# LPC800 register map
File version: 0.2
CPU: CM0 r0p0, little endian, no MPU, no FPU, 2 interrupt priority bits
Registers are 32-bit, read-write, reset 0x0 unless marked. A register's access mark holds for its fields unless they carry their own. Offsets are from the block's base; [hi:lo] are bit positions; {n}, {i} and the like mark numbered series.

## PMU — Power Management Unit (PMU)
Base 0x40020000
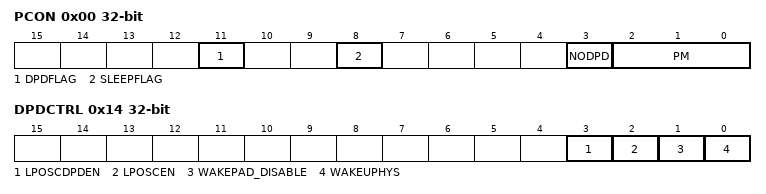
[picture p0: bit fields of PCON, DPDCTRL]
0x00 PCON — Power control register
  [11] DPDFLAG — Deep power-down flag
    0=READ_DEEP_POWER_DOWN_NOT_ENTERED (Read: Deep power-down mode not entered. Write: No effect.); 1=READ_DEEP_POWER_DOWN_ENTERED (Read: Deep power-down mode entered. Write: Clear the Deep power-down flag.)
  [8] SLEEPFLAG — Sleep mode flag
    0=READ_NO_POWER_DOWN_ (Read: No power-down mode entered. LPC11Uxx is in Active mode. Write: No effect.); 1=READ_SLEEPDEEP_SLE (Read: Sleep/Deep-sleep or Deep power-down mode entered. Write: Writing a 1 clears the SLEEPFLAG bit to 0.)
  [3] NODPD — A 1 in this bit prevents entry to Deep power-down mode when 0x3 is written to the PM field above, the SLEEPDEEP bit is set, and a WFI is executed. This bit is cleared only by power-on reset, so writing a one to this bit locks the part in a mode in which Deep power-down mode is blocked.
  [2:0] PM — Power mode
    0=DEFAULT_THE_PART_IS (Default. The part is in active or sleep mode.); 1=ARM_WFI_WILL_ENTER_DEEP_SLEEP (ARM WFI will enter Deep-sleep mode.); 2=ARM_WFI_WILL_ENTER_P (ARM WFI will enter Power-down mode.); 3=ARM_WFI_WILL_ENTER_DEEP_POWER_DOWN (ARM WFI will enter Deep-power down mode (ARM Cortex-M0 core powered-down).)
{0x4+4i} GPREG{i} (i=0..3) — General purpose register 0
  [31:0] GPDATA — Data retained during Deep power-down mode.
0x14 DPDCTRL — Deep power-down control register
  [3] LPOSCDPDEN — Enable the low-power oscillator in Deep power-down mode. Setting this bit causes the low-power oscillator to remain running during Deep power-down mode provided that bit 12 in this register is set as well. You must set this bit for the self wake-up timer to be able to wake up the part from Deep power-down mode. Do not set this bit unless you must use the self wake-up timer to wake up from Deep power-down mode.
    0=DISABLED_; 1=ENABLED_
  [2] LPOSCEN — Enable the low-power oscillator for use with the 10 kHz self wake-up timer clock. You must set this bit if the CLKSEL bit in the self wake-up timer CTRL bit is set. Do not enable the low-power oscillator if the self wake-up timer is clocked by the divided IRC.
    0=DISABLED_; 1=ENABLED_
  [1] WAKEPAD_DISABLE — WAKEUP pin disable. Setting this bit disables the wake-up pin, so it can be used for other purposes. Never set this bit if you intend to use a pin to wake up the part from Deep power-down mode. You can only disable the wake-up pin if the self wake-up timer is enabled and configured. Setting this bit is not necessary if Deep power-down mode is not used.
    0=ENABLED_THE_WAKE_UP (Enabled. The wake-up function is enabled on pin PIO0_4.); 1=DISABLED_SETTING_TH (Disabled. Setting this bit disables the wake-up function on pin PIO0_4.)
  [0] WAKEUPHYS — WAKEUP pin hysteresis enable
    0=DISABLED_HYSTERESIS (Disabled. Hysteresis for WAKUP pin disabled.); 1=ENABLED_HYSTERESIS_ (Enabled. Hysteresis for WAKEUP pin enabled.)

## CMP — Analog comparator
Base 0x40024000
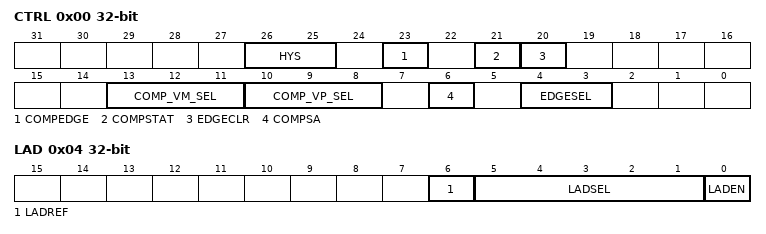
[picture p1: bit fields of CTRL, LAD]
0x00 CTRL — Comparator control register
  [26:25] HYS — Controls the hysteresis of the comparator. When the comparator is outputting a certain state, this is the difference between the selected signals, in the opposite direction from the state being output, that will switch the output.
    0=NONE_THE_OUTPUT_WIL (None (the output will switch as the voltages cross)); 1=5_MV; 2=10_MV; 3=20_MV
  [23] COMPEDGE — Comparator edge-detect status.
  [21] COMPSTAT — Comparator status. This bit reflects the state of the comparator output.
  [20] EDGECLR — Interrupt clear bit. To clear the COMPEDGE bit and thus negate the interrupt request, toggle the EDGECLR bit by first writing a 1 and then a 0.
  [13:11] COMP_VM_SEL — Selects negative voltage input
    0=VOLTAGE_LADDER_OUTPU (voltage ladder output); 1=ACMP_I1; 2=ACMP_I2; 6=INTERNAL_REFERENCE_V (Internal reference voltage)
  [10:8] COMP_VP_SEL — Selects positive voltage input
    0=VOLTAGE_LADDER_OUTPU (Voltage ladder output); 1=ACMP_I1; 2=ACMP_I2; 6=INTERNAL_REFERENCE_V (Internal reference voltage)
  [6] COMPSA — Comparator output control
    0=DIRECT (Comparator output is used directly.); 1=SYNCH (Comparator output is synchronized to the bus clock for output to other modules.)
  [4:3] EDGESEL — This field controls which edges on the comparator output set the COMPEDGE bit (bit 23 below): 00 = Falling edges 01 = Rising edges 1x = Both edges
    0=FALLING_EDGES; 1=RISING_EDGES; 2=BOTH_EDGES_2; 3=BOTH_EDGES_3
0x04 LAD — Voltage ladder register
  [6] LADREF — Selects the reference voltage Vref for the voltage ladder:
    0=SUPPLY_PIN_VDD; 1=VDDCMP_PIN
  [5:1] LADSEL — Voltage ladder value. The reference voltage Vref depends on the LADREF bit below. 00000 = VSS 00001 = 1 x Vref/31 00010 = 2 x Vref/31 ... 11111 = Vref
  [0] LADEN — Voltage ladder enable
